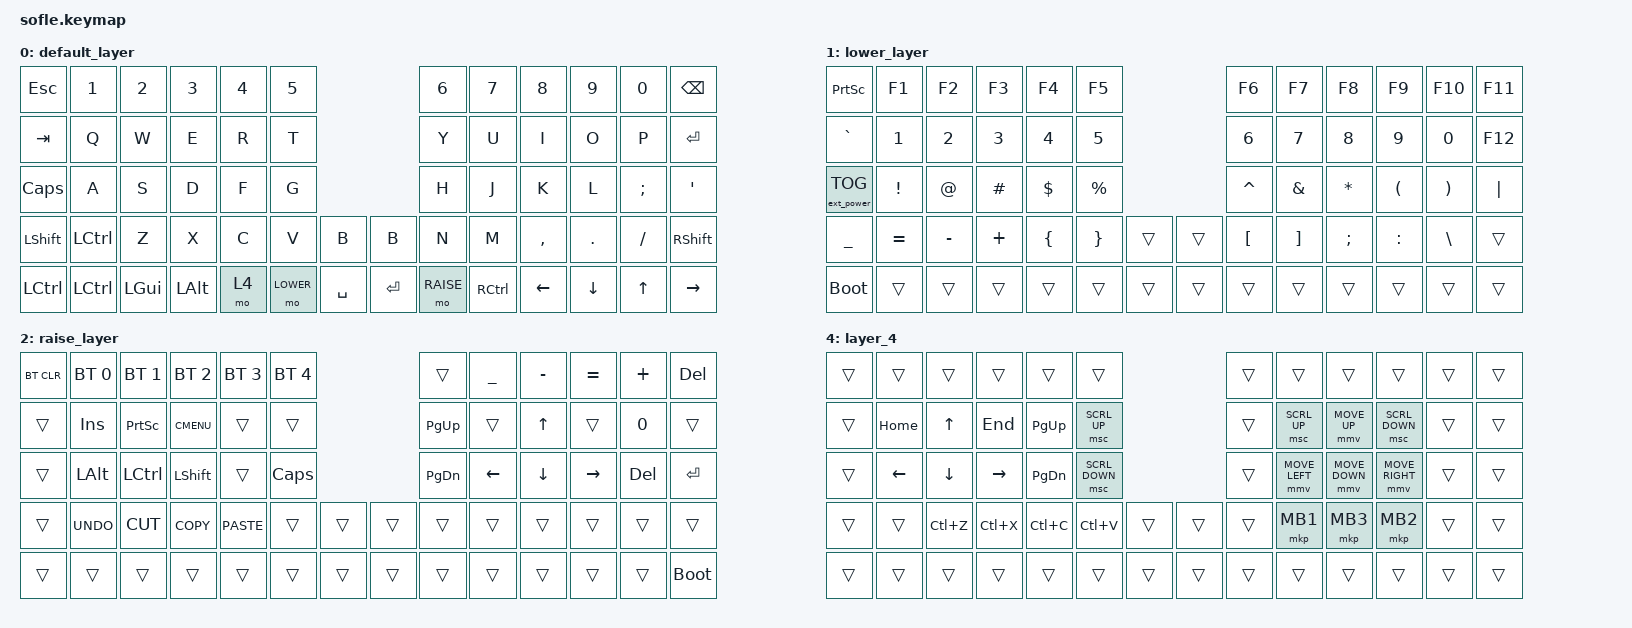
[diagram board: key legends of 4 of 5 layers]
/*
 * Copyright (c) 2020 The ZMK Contributors
 *
 * SPDX-License-Identifier: MIT
 */

#include <behaviors.dtsi>
#include <dt-bindings/zmk/bt.h>
#include <dt-bindings/zmk/ext_power.h>
#include <dt-bindings/zmk/keys.h>
#include <dt-bindings/zmk/pointing.h>
#include <dt-bindings/zmk/rgb.h>

#define BASE 0
#define LOWER 1
#define RAISE 2
#define ADJUST 3

/ {
    // Activate ADJUST layer by pressing raise and lower

    conditional_layers {
        compatible = "zmk,conditional-layers";

        adjust_layer {
            if-layers = <LOWER RAISE>;
            then-layer = <ADJUST>;
        };
    };

    keymap {
        compatible = "zmk,keymap";

        default_layer {
            // ------------------------------------------------------------------------------------------------------------
            // |   `   |  1  |  2  |  3   |  4   |  5   |                   |  6   |  7    |  8    |  9   |   0   |       |
            // |  ESC  |  Q  |  W  |  E   |  R   |  T   |                   |  Y   |  U    |  I    |  O   |   P   | BKSPC |
            // |  TAB  |  A  |  S  |  D   |  F   |  G   |                   |  H   |  J    |  K    |  L   |   ;   |   '   |
            // | SHIFT |  Z  |  X  |  C   |  V   |  B   |  MUTE  |  |       |  N   |  M    |  ,    |  .   |   /   | SHIFT |
            //               | GUI | ALT  | CTRL | LOWER|  ENTER |  | SPACE | RAISE| CTRL  | ALT   | GUI  |

            bindings = <
&kp ESC    &kp N1     &kp N2    &kp N3    &kp N4  &kp N5                           &kp N6     &kp N7     &kp N8     &kp N9    &kp N0    &kp BACKSPACE
&kp TAB    &kp Q      &kp W     &kp E     &kp R   &kp T                            &kp Y      &kp U      &kp I      &kp O     &kp P     &kp RET
&kp CAPS   &kp A      &kp S     &kp D     &kp F   &kp G                            &kp H      &kp J      &kp K      &kp L     &kp SEMI  &kp SQT
&kp LSHFT  &kp LCTRL  &kp Z     &kp X     &kp C   &kp V      &kp B        &kp B    &kp N      &kp M      &kp COMMA  &kp DOT   &kp FSLH  &kp RSHFT
&kp LCTRL  &kp LCTRL  &kp LGUI  &kp LALT  &mo 4   &mo LOWER  &kp SPACE    &kp RET  &mo RAISE  &kp RCTRL  &kp LEFT   &kp DOWN  &kp UP    &kp RIGHT
            >;

            sensor-bindings = <&inc_dec_kp C_VOL_UP C_VOL_DN &inc_dec_kp PG_UP PG_DN>;
        };

        lower_layer {
            // TODO: Some binds are waiting for shifted keycode support.
            // ------------------------------------------------------------------------------------------------------------
            // |       |  F1 |  F2 |  F3  |  F4  |  F5  |                   |  F6  |  F7   |  F8   |  F9  |  F10  |  F11  |
            // |   `   |  1  |  2  |  3   |  4   |  5   |                   |  6   |  7    |  8    |  9   |   0   |  F12  |
            // |       |  !  |  @  |  #   |  $   |  %   |                   |  ^   |  &    |  *    |  (   |   )   |   |   |
            // |       |  =  |  -  |  +   |  {   |  }   |        |  |       |  [   |  ]    |  ;    |  :   |   \   |       |
            //               |     |      |      |      |        |  |       |      |       |       |      |

            bindings = <
&kp PRINTSCREEN    &kp F1     &kp F2     &kp F3    &kp F4    &kp F5                       &kp F6     &kp F7    &kp F8     &kp F9     &kp F10   &kp F11
&kp GRAVE          &kp N1     &kp N2     &kp N3    &kp N4    &kp N5                       &kp N6     &kp N7    &kp N8     &kp N9     &kp N0    &kp F12
&ext_power EP_TOG  &kp EXCL   &kp AT     &kp HASH  &kp DLLR  &kp PRCNT                    &kp CARET  &kp AMPS  &kp ASTRK  &kp LPAR   &kp RPAR  &kp PIPE
&kp UNDERSCORE     &kp EQUAL  &kp MINUS  &kp PLUS  &kp LBRC  &kp RBRC   &trans    &trans  &kp LBKT   &kp RBKT  &kp SEMI   &kp COLON  &kp BSLH  &trans
&bootloader        &trans     &trans     &trans    &trans    &trans     &trans    &trans  &trans     &trans    &trans     &trans     &trans    &trans
            >;

            sensor-bindings = <&inc_dec_kp C_VOL_UP C_VOL_DN &inc_dec_kp PG_UP PG_DN>;
        };

        raise_layer {
            // ------------------------------------------------------------------------------------------------------------
            // | BTCLR | BT1  | BT2  |  BT3  |  BT4  |  BT5 |                |      |      |       |      |       |       |
            // |       | INS  | PSCR | GUI   |       |      |                | PGUP |      |   ^   |      |       |       |
            // |       | ALT  | CTRL | SHIFT |       | CAPS |                | PGDN |   <- |   v   |  ->  |  DEL  | BKSPC |
            // |       | UNDO | CUT  | COPY  | PASTE |      |      |  |      |      |      |       |      |       |       |
            //                |      |       |       |      |      |  |      |      |      |       |      |

            bindings = <
&bt BT_CLR  &bt BT_SEL 0  &bt BT_SEL 1  &bt BT_SEL 2  &bt BT_SEL 3  &bt BT_SEL 4                    &trans     &kp UNDERSCORE  &kp MINUS  &kp EQUAL  &kp PLUS  &kp DELETE
&trans      &kp INS       &kp PSCRN     &kp K_CMENU   &trans        &trans                          &kp PG_UP  &trans          &kp UP     &trans     &kp N0    &trans
&trans      &kp LALT      &kp LCTRL     &kp LSHFT     &trans        &kp CLCK                        &kp PG_DN  &kp LEFT        &kp DOWN   &kp RIGHT  &kp DEL   &kp ENTER
&trans      &kp K_UNDO    &kp K_CUT     &kp K_COPY    &kp K_PASTE   &trans        &trans    &trans  &trans     &trans          &trans     &trans     &trans    &trans
&trans      &trans        &trans        &trans        &trans        &trans        &trans    &trans  &trans     &trans          &trans     &trans     &trans    &bootloader
            >;

            sensor-bindings = <&inc_dec_kp C_VOL_UP C_VOL_DN &inc_dec_kp PG_UP PG_DN>;
        };

        adjust_layer {
            // ----------------------------------------------------------------------------------------------------------------------------
            // | BTCLR  |  BT1    |  BT2    |   BT3   |   BT4   |   BT5   |                  |      |      |       |      |       |       |
            // | EXTPWR | RGB_HUD | RGB_HUI | RGB_SAD | RGB_SAI | RGB_EFF |                  |      |      |       |      |       |       |
            // |        | RGB_BRD | RGB_BRI |         |         |         |                  |      |      |       |      |       |       |
            // |        |         |         |         |         |         | RGB_TOG | |      |      |      |       |      |       |       |
            //                    |         |         |         |         |         | |      |      |      |       |      |

            bindings = <
&bt BT_CLR         &bt BT_SEL 0     &bt BT_SEL 1     &bt BT_SEL 2     &bt BT_SEL 3     &bt BT_SEL 4                     &none            &none  &none  &none  &none  &none
&ext_power EP_TOG  &rgb_ug RGB_HUD  &rgb_ug RGB_HUI  &rgb_ug RGB_SAD  &rgb_ug RGB_SAI  &rgb_ug RGB_EFF                  &none            &none  &none  &none  &none  &ext_power EP_TOG
&none              &rgb_ug RGB_BRD  &rgb_ug RGB_BRI  &none            &none            &rgb_ug RGB_TOG                  &rgb_ug RGB_TOG  &none  &none  &none  &none  &none
&none              &none            &none            &none            &none            &none            &none    &none  &none            &none  &none  &none  &none  &none
&none              &none            &none            &none            &none            &none            &none    &none  &none            &none
            >;
        };

        layer_4 {
            bindings = <
&trans  &trans          &trans          &trans     &trans         &trans                            &trans  &trans          &trans          &trans           &trans  &trans
&trans  &kp HOME        &kp UP_ARROW    &kp END    &kp PAGE_UP    &msc SCRL_UP                      &trans  &msc SCRL_UP    &mmv MOVE_UP    &msc SCRL_DOWN   &trans  &trans
&trans  &kp LEFT_ARROW  &kp DOWN_ARROW  &kp RIGHT  &kp PAGE_DOWN  &msc SCRL_DOWN                    &trans  &mmv MOVE_LEFT  &mmv MOVE_DOWN  &mmv MOVE_RIGHT  &trans  &trans
&trans  &trans          &kp LC(Z)       &kp LC(X)  &kp LC(C)      &kp LC(V)       &trans    &trans  &trans  &mkp MB1        &mkp MB3        &mkp MB2         &trans  &trans
&trans  &trans          &trans          &trans     &trans         &trans          &trans    &trans  &trans  &trans          &trans          &trans           &trans  &trans
            >;
        };
    };
};
